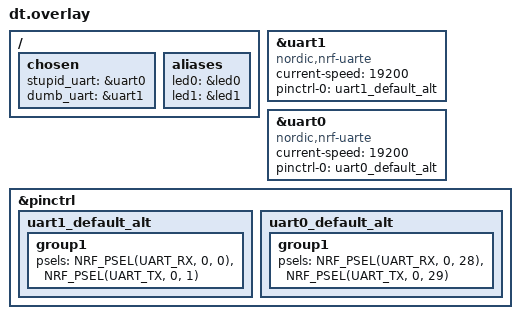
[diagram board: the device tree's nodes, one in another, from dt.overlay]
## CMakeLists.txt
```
#
# Copyright (c) 2020 Nordic Semiconductor
#
# SPDX-License-Identifier: LicenseRef-Nordic-5-Clause
#

cmake_minimum_required(VERSION 3.20.0)

find_package(Zephyr REQUIRED HINTS $ENV{ZEPHYR_BASE})
project(serial_app)

# NORDIC SDK APP START
target_sources(app PRIVATE src/main.c)
# NORDIC SDK APP END
```

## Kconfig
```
#
# Copyright (c) 2021 Nordic Semiconductor ASA
#
# SPDX-License-Identifier: LicenseRef-Nordic-5-Clause
#

menu "HTTPS client sample"

config SAMPLE_TFM_MBEDTLS
	bool "Use TF-M and MbedTLS"
	depends on NRF_MODEM_LIB
	help
	  Use TF-M and MbedTLS in this sample instead of using
	  the offloaded TLS stack in the modem.

config HTTPS_HOSTNAME
	string "HTTPS hostname"
	default "www.stealth-intel.com"

endmenu

menu "Zephyr Kernel"
source "Kconfig.zephyr"
endmenu
```

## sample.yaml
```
sample:
  name: HTTPS client sample
tests:
  sample.net.https_client:
    sysbuild: true
    build_only: true
    integration_platforms:
      - nrf9160dk/nrf9160/ns
      - nrf9161dk/nrf9161/ns
      - nrf9151dk/nrf9151/ns
      - nrf7002dk/nrf5340/cpuapp/ns
      - native_sim
    platform_allow:
      - nrf9160dk/nrf9160/ns
      - nrf9161dk/nrf9161/ns
      - nrf9151dk/nrf9151/ns
      - nrf7002dk/nrf5340/cpuapp/ns
      - native_sim
    tags: ci_build sysbuild
  sample.net.https_client.lte.tfm-mbedtls:
    sysbuild: true
    build_only: true
    extra_args: OVERLAY_CONFIG="overlay-tfm-nrf91.conf"
    integration_platforms:
      - nrf9160dk/nrf9160/ns
      - nrf9161dk/nrf9161/ns
    platform_allow:
      - nrf9160dk/nrf9160/ns
      - nrf9161dk/nrf9161/ns
      - nrf9151dk/nrf9151/ns
    tags: ci_build sysbuild
  sample.net.https_client.lte.pdn-ipv4:
    sysbuild: true
    build_only: true
    extra_args: OVERLAY_CONFIG="overlay-pdn-nrf91-ipv4.conf"
    integration_platforms:
      - nrf9160dk/nrf9160/ns
      - nrf9161dk/nrf9161/ns
      - nrf9151dk/nrf9151/ns
    platform_allow:
      - nrf9160dk/nrf9160/ns
      - nrf9161dk/nrf9161/ns
      - nrf9151dk/nrf9151/ns
    tags: ci_build sysbuild
```

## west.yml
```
manifest:
  version: "0.10"
  remotes:
    - name: ncs
      url-base: https://github.com/nrfconnect

  projects:
    - name: nrf
      remote: ncs
      repo-path: sdk-nrf
      revision: v2.7.0
      import: true
    - name: zephyr
      remote: ncs
      repo-path: zephyr
      revision: v3.4.99-ncs1
      import: true
    - name: mcuboot
      remote: ncs
      repo-path: mcuboot
      revision: v2.0.99-ncs2
      import: true
    - name: nrfxlib
      remote: ncs
      repo-path: nrfxlib
      revision: v2.7.0
      import: true

  self:
    path: nrf91_windows
```

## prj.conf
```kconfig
#
# Copyright (c) 2023 Nordic Semiconductor ASA
#
# SPDX-License-Identifier: LicenseRef-Nordic-5-Clause
#

# General
CONFIG_HEAP_MEM_POOL_SIZE=1024
CONFIG_MAIN_STACK_SIZE=4096

# Logging
CONFIG_LOG=y

# Peripherals
CONFIG_SERIAL=y
CONFIG_UART_INTERRUPT_DRIVEN=y
CONFIG_GPIO=y

# Printk over RTT
CONFIG_USE_SEGGER_RTT=y
CONFIG_RTT_CONSOLE=y
CONFIG_UART_CONSOLE=n
```

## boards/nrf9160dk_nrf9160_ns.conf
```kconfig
#
# Copyright (c) 2023 Nordic Semiconductor ASA
#
# SPDX-License-Identifier: LicenseRef-Nordic-5-Clause
#

# Configuration file for nRF9160 DK
# This file is merged with prj.conf in the application folder, and options
# set here will take precedence if they are present in both files.
CONFIG_USE_SEGGER_RTT=y
CONFIG_RTT_CONSOLE=y
CONFIG_UART_CONSOLE=n

# Heap and stacks
CONFIG_HEAP_MEM_POOL_SIZE=4096
CONFIG_MAIN_STACK_SIZE=4096
CONFIG_SYSTEM_WORKQUEUE_STACK_SIZE=4096

# LED control
CONFIG_DK_LIBRARY=y

# Disable Duplicate Address Detection (DAD)
# due to not being properly implemented for offloaded interfaces.
CONFIG_NET_IPV6_NBR_CACHE=n
CONFIG_NET_IPV6_MLD=n

# Connection Manager and Connectivity layer
CONFIG_NRF_MODEM_LIB_NET_IF=y

# AT Host
CONFIG_UART_INTERRUPT_DRIVEN=y
CONFIG_AT_HOST_LIBRARY=y

# Modem key management
CONFIG_MODEM_KEY_MGMT=y
```

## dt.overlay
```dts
/* SPDX-License-Identifier: LicenseRef-Nordic-5-Clause */

/ {
	chosen {
	  stupid_uart = &uart0;
	  dumb_uart = &uart1;
	};

	aliases {
		led0 = &led0;
		led1 = &led1;
	  };
  };
  
&uart1 {
	status = "okay";
    compatible = "nordic,nrf-uarte";
	current-speed = <19200>;
	pinctrl-0 = <&uart1_default_alt>;
};

&uart0 {
	status = "okay";
    compatible = "nordic,nrf-uarte";
	current-speed = <19200>;
	pinctrl-0 = <&uart0_default_alt>;
};

&pinctrl {
	uart1_default_alt: uart1_default_alt {
		group1 {
			psels = <NRF_PSEL(UART_RX, 0, 0)>,
				<NRF_PSEL(UART_TX, 0, 1)>;
		};
	};
	uart0_default_alt: uart0_default_alt {
		group1 {
			psels = <NRF_PSEL(UART_RX, 0, 28)>,
				<NRF_PSEL(UART_TX, 0, 29)>;
		};
	};
};
```

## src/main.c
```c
/*
 * Copyright (c) 2022 Libre Solar Technologies GmbH
 *
 * SPDX-License-Identifier: Apache-2.0
 */

#include <zephyr/kernel.h>
#include <zephyr/device.h>
#include <zephyr/drivers/uart.h>
#include <zephyr/drivers/gpio.h>
#include <string.h>

/*TODO
  - Verify checksum to confirm integrity of messages. Report error if messages are corrupted.
  - Pass in references to the specific uart device to reduce duplication of functions.
*/

#define UART0_DEVICE_NODE DT_CHOSEN(stupid_uart)
#define UART1_DEVICE_NODE DT_CHOSEN(dumb_uart)

#define MSG_SIZE 200
/* size of stack area used by each thread */
#define STACKSIZE 1024
/* scheduling priority used by each thread */
#define PRIORITY 7

#define SLEEP_TIME_MS   1000

#define LED0_NODE DT_ALIAS(led0)
#define LED1_NODE DT_ALIAS(led1)

/* queue to store up to 20 messages (aligned to 4-byte boundary) */
K_MSGQ_DEFINE(uart0_msgq, MSG_SIZE, 20, 4);
K_MSGQ_DEFINE(uart1_msgq, MSG_SIZE, 20, 4);

static const struct device *const uart0_dev = DEVICE_DT_GET(UART0_DEVICE_NODE);
static const struct device *const uart1_dev = DEVICE_DT_GET(UART1_DEVICE_NODE);

static const struct gpio_dt_spec led = GPIO_DT_SPEC_GET(LED1_NODE, gpios);

/* receive buffer used in UART ISR callback */
static char rx_buf0[MSG_SIZE];
static int rx_buf0_pos;

/* receive buffer used in UART ISR callback */
static char rx_buf1[MSG_SIZE];
static int rx_buf1_pos;

K_THREAD_STACK_DEFINE(threadb_stack_area, STACKSIZE);
struct k_thread threadb_data;

K_THREAD_STACK_DEFINE(thread0_stack_area, STACKSIZE);
struct k_thread thread0_data;

K_THREAD_STACK_DEFINE(thread1_stack_area, STACKSIZE);
struct k_thread thread1_data;


/*
 * Read characters from UART until line end is detected. Afterwards push the
 * data to the message queue.
 */
void uart0_serial_cb(const struct device *dev, void *user_data)
{
	uint8_t c;

	if (!uart_irq_update(uart0_dev)) {
		return;
	}

	if (!uart_irq_rx_ready(uart0_dev)) {
		return;
	}

	/* read until FIFO empty */
	while (uart_fifo_read(uart0_dev, &c, 1) == 1) {
		if ((c == '\n' || c == '\r') && rx_buf0_pos > 0) {
			/* terminate string */
			rx_buf0[rx_buf0_pos] = '\0';

			/* if queue is full, message is silently dropped */
			k_msgq_put(&uart0_msgq, &rx_buf0, K_NO_WAIT);

			/* reset the buffer (it was copied to the msgq) */
			rx_buf0_pos = 0;
		} else if (rx_buf0_pos < (sizeof(rx_buf0) - 1)) {
			rx_buf0[rx_buf0_pos++] = c;
		}
		/* else: characters beyond buffer size are dropped */
	}
}
/*
 * Read characters from UART until line end is detected. Afterwards push the
 * data to the message queue.
 */
void uart1_serial_cb(const struct device *dev, void *user_data)
{
	uint8_t c;

	if (!uart_irq_update(uart1_dev)) {
		return;
	}

	if (!uart_irq_rx_ready(uart1_dev)) {
		return;
	}

	/* read until FIFO empty */
	while (uart_fifo_read(uart1_dev, &c, 1) == 1) {
		if ((c == '\n' || c == '\r') && rx_buf1_pos > 0) {
			/* terminate string */
			rx_buf1[rx_buf1_pos] = '\0';

			/* if queue is full, message is silently dropped */
			k_msgq_put(&uart1_msgq, &rx_buf1, K_NO_WAIT);

			/* reset the buffer (it was copied to the msgq) */
			rx_buf1_pos = 0;
		} else if (rx_buf1_pos < (sizeof(rx_buf1) - 1)) {
			rx_buf1[rx_buf1_pos++] = c;
		}
		/* else: characters beyond buffer size are dropped */
	}
}

/*
 * Print a null-terminated string character by character to the UART interface
 */
void print_uart0(char *buf)
{
	int msg_len = strlen(buf);

	for (int i = 0; i < msg_len; i++) {
		uart_poll_out(uart0_dev, buf[i]);
	}
}
/*
 * Print a null-terminated string character by character to the UART interface
 */
void print_uart1(char *buf)
{
	int msg_len = strlen(buf);

	for (int i = 0; i < msg_len; i++) {
		uart_poll_out(uart1_dev, buf[i]);
	}
}

void blink_thread(void *, void *, void *)
{
	printk("blink thread\n\r");

	/*toggle the led*/
	while(1) {
		gpio_pin_toggle_dt(&led);
    	k_msleep(SLEEP_TIME_MS);
	}
}

void uart0_thread(void *, void *, void *)
{
	char tx_buf0[MSG_SIZE];

	printk("uart0 thread\n\r");

	/* indefinitely wait for strings, then echo back */
	while (1) {

		if (k_msgq_get(&uart0_msgq, &tx_buf0, K_FOREVER) == 0) {
			print_uart0(tx_buf0);
			print_uart0("\r\n");
		}
	}

}

void uart1_thread(void *, void *, void *)
{
	char tx_buf1[MSG_SIZE];

	printk("uart1 thread\n\r");

	/* indefinitely wait for strings, then echo back */
	while (1) {

	    if (k_msgq_get(&uart1_msgq, &tx_buf1, K_FOREVER) == 0) {
			print_uart1(tx_buf1);
			print_uart1("\r\n");
	    }
	}

}


int main(void)
{
	int ret;

    printk("starting main\n\r");


	if (!device_is_ready(uart0_dev)) {
		printk("UART0 device not found!");
		return 0;
	}

	if (!device_is_ready(uart1_dev)) {
		printk("UART1 device not found!");
		return 0;
	}

	if (!gpio_is_ready_dt(&led)) {
		return 0;
	}

	ret = gpio_pin_configure_dt(&led, GPIO_OUTPUT_ACTIVE);
	if (ret < 0) {
		return 0;
	}

	/* configure interrupt and callback to receive data */
	ret = uart_irq_callback_user_data_set(uart0_dev, uart0_serial_cb, NULL);

	if (ret < 0) {
		if (ret == -ENOTSUP) {
			printk("UART0: Interrupt-driven UART API support not enabled\n");
		} else if (ret == -ENOSYS) {
			printk("UART0: UART device does not support interrupt-driven API\n");
		} else {
			printk("UART0: Error setting UART callback: %d\n", ret);
		}
		return 0;
	}
	uart_irq_rx_enable(uart0_dev);

	/* configure interrupt and callback to receive data */
	ret = uart_irq_callback_user_data_set(uart1_dev, uart1_serial_cb, NULL);

	if (ret < 0) {
		if (ret == -ENOTSUP) {
			printk("UART1: Interrupt-driven UART API support not enabled\n");
		} else if (ret == -ENOSYS) {
			printk("UART1: UART device does not support interrupt-driven API\n");
		} else {
			printk("UART1: Error setting UART callback: %d\n", ret);
		}
		return 0;
	}
	uart_irq_rx_enable(uart1_dev);

	print_uart0("UART0: Hello!\r\n");
	print_uart1("UART1: Hello!\r\n");

	k_thread_create(&threadb_data, threadb_stack_area,
					K_THREAD_STACK_SIZEOF(threadb_stack_area),
					blink_thread,
					NULL, NULL, NULL,
					PRIORITY, 0, K_MSEC(500));
	k_thread_start(&threadb_data);

	k_thread_create(&thread0_data, thread0_stack_area,
                    K_THREAD_STACK_SIZEOF(thread0_stack_area),
                    uart0_thread,
                    NULL, NULL, NULL,
                    PRIORITY, 0, K_MSEC(500));
    k_thread_start(&thread0_data);

	k_thread_create(&thread1_data, thread1_stack_area,
                    K_THREAD_STACK_SIZEOF(thread1_stack_area),
                    uart1_thread,
                    NULL, NULL, NULL,
                    PRIORITY, 0, K_MSEC(500));
    k_thread_start(&thread1_data);

	//the job is done. do nothing for now.
	while (1)
	{
		k_msleep(SLEEP_TIME_MS);
	}
	

	return 0;
}


/* Static way to define threads */
/*
K_THREAD_DEFINE(blink_thread_id, STACKSIZE, blink_thread, NULL, NULL, NULL, PRIORITY, 0, 0);
K_THREAD_DEFINE(uart0_thread_id, STACKSIZE, uart0_thread, NULL, NULL, NULL, PRIORITY, 0, 0);
K_THREAD_DEFINE(uart1_thread_id, STACKSIZE, uart1_thread, NULL, NULL, NULL, PRIORITY, 0, 0);
*/
```
